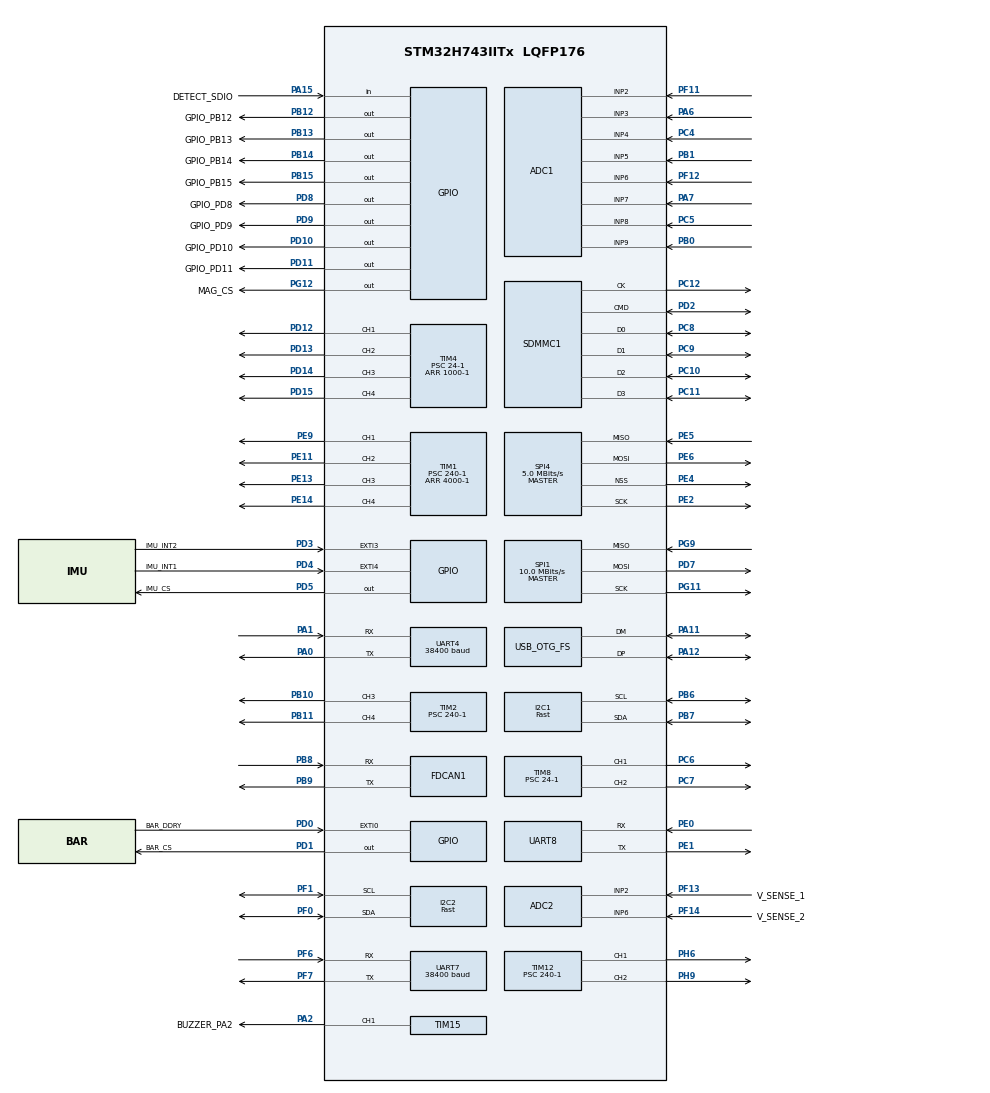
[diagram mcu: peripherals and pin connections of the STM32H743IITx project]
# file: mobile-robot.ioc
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ADC1.Channel-0\#ChannelRegularConversion=ADC_CHANNEL_2
ADC1.ClockPrescaler=ADC_CLOCK_ASYNC_DIV2
ADC1.NbrOfConversionFlag=1
ADC1.OffsetNumber-0\#ChannelRegularConversion=ADC_OFFSET_NONE
ADC1.OffsetSignedSaturation-0\#ChannelRegularConversion=DISABLE
ADC1.Rank-0\#ChannelRegularConversion=1
ADC1.SamplingTime-0\#ChannelRegularConversion=ADC_SAMPLETIME_1CYCLE_5
ADC1.master=1
ADC2.Channel-0\#ChannelRegularConversion=ADC_CHANNEL_2
ADC2.ClockPrescaler=ADC_CLOCK_ASYNC_DIV2
ADC2.NbrOfConversionFlag=1
ADC2.OffsetNumber-0\#ChannelRegularConversion=ADC_OFFSET_NONE
ADC2.OffsetSignedSaturation-0\#ChannelRegularConversion=DISABLE
ADC2.Rank-0\#ChannelRegularConversion=1
ADC2.SamplingTime-0\#ChannelRegularConversion=ADC_SAMPLETIME_1CYCLE_5
CORTEX_M7.default_mode_Activation=1
Dma.I2C1_RX.6.Direction=DMA_PERIPH_TO_MEMORY
Dma.I2C1_RX.6.EventEnable=DISABLE
Dma.I2C1_RX.6.FIFOMode=DMA_FIFOMODE_DISABLE
Dma.I2C1_RX.6.Instance=DMA1_Stream6
Dma.I2C1_RX.6.MemDataAlignment=DMA_MDATAALIGN_BYTE
Dma.I2C1_RX.6.MemInc=DMA_MINC_ENABLE
Dma.I2C1_RX.6.Mode=DMA_NORMAL
Dma.I2C1_RX.6.PeriphDataAlignment=DMA_PDATAALIGN_BYTE
Dma.I2C1_RX.6.PeriphInc=DMA_PINC_DISABLE
Dma.I2C1_RX.6.Polarity=HAL_DMAMUX_REQ_GEN_RISING
Dma.I2C1_RX.6.Priority=DMA_PRIORITY_LOW
Dma.I2C1_RX.6.RequestNumber=1
Dma.I2C1_RX.6.SignalID=NONE
Dma.I2C1_RX.6.SyncEnable=DISABLE
Dma.I2C1_RX.6.SyncPolarity=HAL_DMAMUX_SYNC_NO_EVENT
Dma.I2C1_RX.6.SyncRequestNumber=1
Dma.I2C1_RX.6.SyncSignalID=NONE
Dma.I2C1_TX.7.Direction=DMA_MEMORY_TO_PERIPH
Dma.I2C1_TX.7.EventEnable=DISABLE
Dma.I2C1_TX.7.FIFOMode=DMA_FIFOMODE_DISABLE
Dma.I2C1_TX.7.Instance=DMA1_Stream7
Dma.I2C1_TX.7.MemDataAlignment=DMA_MDATAALIGN_BYTE
Dma.I2C1_TX.7.MemInc=DMA_MINC_ENABLE
Dma.I2C1_TX.7.Mode=DMA_NORMAL
Dma.I2C1_TX.7.PeriphDataAlignment=DMA_PDATAALIGN_BYTE
Dma.I2C1_TX.7.PeriphInc=DMA_PINC_DISABLE
Dma.I2C1_TX.7.Polarity=HAL_DMAMUX_REQ_GEN_RISING
Dma.I2C1_TX.7.Priority=DMA_PRIORITY_LOW
Dma.I2C1_TX.7.RequestNumber=1
Dma.I2C1_TX.7.SignalID=NONE
Dma.I2C1_TX.7.SyncEnable=DISABLE
Dma.I2C1_TX.7.SyncPolarity=HAL_DMAMUX_SYNC_NO_EVENT
Dma.I2C1_TX.7.SyncRequestNumber=1
Dma.I2C1_TX.7.SyncSignalID=NONE
Dma.Request0=UART4_RX
Dma.Request1=UART4_TX
Dma.Request2=UART7_RX
Dma.Request3=UART7_TX
Dma.Request4=UART8_RX
Dma.Request5=UART8_TX
Dma.Request6=I2C1_RX
Dma.Request7=I2C1_TX
Dma.Request8=SPI1_RX
Dma.Request9=SPI1_TX
Dma.SPI1_RX.8.Direction=DMA_PERIPH_TO_MEMORY
Dma.SPI1_RX.8.EventEnable=DISABLE
Dma.SPI1_RX.8.FIFOMode=DMA_FIFOMODE_DISABLE
Dma.SPI1_RX.8.Instance=DMA2_Stream0
Dma.SPI1_RX.8.MemDataAlignment=DMA_MDATAALIGN_BYTE
Dma.SPI1_RX.8.MemInc=DMA_MINC_ENABLE
Dma.SPI1_RX.8.Mode=DMA_NORMAL
Dma.SPI1_RX.8.PeriphDataAlignment=DMA_PDATAALIGN_BYTE
Dma.SPI1_RX.8.PeriphInc=DMA_PINC_DISABLE
Dma.SPI1_RX.8.Polarity=HAL_DMAMUX_REQ_GEN_RISING
Dma.SPI1_RX.8.Priority=DMA_PRIORITY_LOW
Dma.SPI1_RX.8.RequestNumber=1
Dma.SPI1_RX.8.SignalID=NONE
Dma.SPI1_RX.8.SyncEnable=DISABLE
Dma.SPI1_RX.8.SyncPolarity=HAL_DMAMUX_SYNC_NO_EVENT
Dma.SPI1_RX.8.SyncRequestNumber=1
Dma.SPI1_RX.8.SyncSignalID=NONE
Dma.SPI1_TX.9.Direction=DMA_MEMORY_TO_PERIPH
Dma.SPI1_TX.9.EventEnable=DISABLE
Dma.SPI1_TX.9.FIFOMode=DMA_FIFOMODE_DISABLE
Dma.SPI1_TX.9.Instance=DMA2_Stream1
Dma.SPI1_TX.9.MemDataAlignment=DMA_MDATAALIGN_BYTE
Dma.SPI1_TX.9.MemInc=DMA_MINC_ENABLE
Dma.SPI1_TX.9.Mode=DMA_NORMAL
Dma.SPI1_TX.9.PeriphDataAlignment=DMA_PDATAALIGN_BYTE
Dma.SPI1_TX.9.PeriphInc=DMA_PINC_DISABLE
Dma.SPI1_TX.9.Polarity=HAL_DMAMUX_REQ_GEN_RISING
Dma.SPI1_TX.9.Priority=DMA_PRIORITY_LOW
Dma.SPI1_TX.9.RequestNumber=1
Dma.SPI1_TX.9.SignalID=NONE
Dma.SPI1_TX.9.SyncEnable=DISABLE
Dma.SPI1_TX.9.SyncPolarity=HAL_DMAMUX_SYNC_NO_EVENT
Dma.SPI1_TX.9.SyncRequestNumber=1
Dma.SPI1_TX.9.SyncSignalID=NONE
Dma.UART4_RX.0.Direction=DMA_PERIPH_TO_MEMORY
Dma.UART4_RX.0.EventEnable=DISABLE
Dma.UART4_RX.0.FIFOMode=DMA_FIFOMODE_DISABLE
Dma.UART4_RX.0.Instance=DMA1_Stream0
Dma.UART4_RX.0.MemDataAlignment=DMA_MDATAALIGN_BYTE
Dma.UART4_RX.0.MemInc=DMA_MINC_ENABLE
Dma.UART4_RX.0.Mode=DMA_NORMAL
Dma.UART4_RX.0.PeriphDataAlignment=DMA_PDATAALIGN_BYTE
Dma.UART4_RX.0.PeriphInc=DMA_PINC_DISABLE
Dma.UART4_RX.0.Polarity=HAL_DMAMUX_REQ_GEN_RISING
Dma.UART4_RX.0.Priority=DMA_PRIORITY_LOW
Dma.UART4_RX.0.RequestNumber=1
Dma.UART4_RX.0.SignalID=NONE
Dma.UART4_RX.0.SyncEnable=DISABLE
Dma.UART4_RX.0.SyncPolarity=HAL_DMAMUX_SYNC_NO_EVENT
Dma.UART4_RX.0.SyncRequestNumber=1
Dma.UART4_RX.0.SyncSignalID=NONE
Dma.UART4_TX.1.Direction=DMA_MEMORY_TO_PERIPH
Dma.UART4_TX.1.EventEnable=DISABLE
Dma.UART4_TX.1.FIFOMode=DMA_FIFOMODE_DISABLE
Dma.UART4_TX.1.Instance=DMA1_Stream1
Dma.UART4_TX.1.MemDataAlignment=DMA_MDATAALIGN_BYTE
Dma.UART4_TX.1.MemInc=DMA_MINC_ENABLE
Dma.UART4_TX.1.Mode=DMA_NORMAL
Dma.UART4_TX.1.PeriphDataAlignment=DMA_PDATAALIGN_BYTE
Dma.UART4_TX.1.PeriphInc=DMA_PINC_DISABLE
Dma.UART4_TX.1.Polarity=HAL_DMAMUX_REQ_GEN_RISING
Dma.UART4_TX.1.Priority=DMA_PRIORITY_LOW
Dma.UART4_TX.1.RequestNumber=1
Dma.UART4_TX.1.SignalID=NONE
Dma.UART4_TX.1.SyncEnable=DISABLE
Dma.UART4_TX.1.SyncPolarity=HAL_DMAMUX_SYNC_NO_EVENT
Dma.UART4_TX.1.SyncRequestNumber=1
Dma.UART4_TX.1.SyncSignalID=NONE
Dma.UART7_RX.2.Direction=DMA_PERIPH_TO_MEMORY
Dma.UART7_RX.2.EventEnable=DISABLE
Dma.UART7_RX.2.FIFOMode=DMA_FIFOMODE_DISABLE
Dma.UART7_RX.2.Instance=DMA1_Stream2
Dma.UART7_RX.2.MemDataAlignment=DMA_MDATAALIGN_BYTE
Dma.UART7_RX.2.MemInc=DMA_MINC_ENABLE
Dma.UART7_RX.2.Mode=DMA_NORMAL
Dma.UART7_RX.2.PeriphDataAlignment=DMA_PDATAALIGN_BYTE
Dma.UART7_RX.2.PeriphInc=DMA_PINC_DISABLE
Dma.UART7_RX.2.Polarity=HAL_DMAMUX_REQ_GEN_RISING
Dma.UART7_RX.2.Priority=DMA_PRIORITY_LOW
Dma.UART7_RX.2.RequestNumber=1
Dma.UART7_RX.2.SignalID=NONE
Dma.UART7_RX.2.SyncEnable=DISABLE
Dma.UART7_RX.2.SyncPolarity=HAL_DMAMUX_SYNC_NO_EVENT
Dma.UART7_RX.2.SyncRequestNumber=1
Dma.UART7_RX.2.SyncSignalID=NONE
Dma.UART7_TX.3.Direction=DMA_MEMORY_TO_PERIPH
Dma.UART7_TX.3.EventEnable=DISABLE
Dma.UART7_TX.3.FIFOMode=DMA_FIFOMODE_DISABLE
Dma.UART7_TX.3.Instance=DMA1_Stream3
Dma.UART7_TX.3.MemDataAlignment=DMA_MDATAALIGN_BYTE
Dma.UART7_TX.3.MemInc=DMA_MINC_ENABLE
Dma.UART7_TX.3.Mode=DMA_NORMAL
Dma.UART7_TX.3.PeriphDataAlignment=DMA_PDATAALIGN_BYTE
Dma.UART7_TX.3.PeriphInc=DMA_PINC_DISABLE
Dma.UART7_TX.3.Polarity=HAL_DMAMUX_REQ_GEN_RISING
Dma.UART7_TX.3.Priority=DMA_PRIORITY_LOW
Dma.UART7_TX.3.RequestNumber=1
Dma.UART7_TX.3.SignalID=NONE
Dma.UART7_TX.3.SyncEnable=DISABLE
Dma.UART7_TX.3.SyncPolarity=HAL_DMAMUX_SYNC_NO_EVENT
Dma.UART7_TX.3.SyncRequestNumber=1
Dma.UART7_TX.3.SyncSignalID=NONE
Dma.UART8_RX.4.Direction=DMA_PERIPH_TO_MEMORY
Dma.UART8_RX.4.EventEnable=DISABLE
Dma.UART8_RX.4.FIFOMode=DMA_FIFOMODE_DISABLE
Dma.UART8_RX.4.Instance=DMA1_Stream4
Dma.UART8_RX.4.MemDataAlignment=DMA_MDATAALIGN_BYTE
Dma.UART8_RX.4.MemInc=DMA_MINC_ENABLE
Dma.UART8_RX.4.Mode=DMA_NORMAL
Dma.UART8_RX.4.PeriphDataAlignment=DMA_PDATAALIGN_BYTE
Dma.UART8_RX.4.PeriphInc=DMA_PINC_DISABLE
Dma.UART8_RX.4.Polarity=HAL_DMAMUX_REQ_GEN_RISING
Dma.UART8_RX.4.Priority=DMA_PRIORITY_LOW
Dma.UART8_RX.4.RequestNumber=1
Dma.UART8_RX.4.SignalID=NONE
Dma.UART8_RX.4.SyncEnable=DISABLE
Dma.UART8_RX.4.SyncPolarity=HAL_DMAMUX_SYNC_NO_EVENT
Dma.UART8_RX.4.SyncRequestNumber=1
Dma.UART8_RX.4.SyncSignalID=NONE
Dma.UART8_TX.5.Direction=DMA_MEMORY_TO_PERIPH
Dma.UART8_TX.5.EventEnable=DISABLE
Dma.UART8_TX.5.FIFOMode=DMA_FIFOMODE_DISABLE
Dma.UART8_TX.5.Instance=DMA1_Stream5
Dma.UART8_TX.5.MemDataAlignment=DMA_MDATAALIGN_BYTE
Dma.UART8_TX.5.MemInc=DMA_MINC_ENABLE
Dma.UART8_TX.5.Mode=DMA_NORMAL
Dma.UART8_TX.5.PeriphDataAlignment=DMA_PDATAALIGN_BYTE
Dma.UART8_TX.5.PeriphInc=DMA_PINC_DISABLE
Dma.UART8_TX.5.Polarity=HAL_DMAMUX_REQ_GEN_RISING
Dma.UART8_TX.5.Priority=DMA_PRIORITY_LOW
Dma.UART8_TX.5.RequestNumber=1
Dma.UART8_TX.5.SignalID=NONE
Dma.UART8_TX.5.SyncEnable=DISABLE
Dma.UART8_TX.5.SyncPolarity=HAL_DMAMUX_SYNC_NO_EVENT
Dma.UART8_TX.5.SyncRequestNumber=1
Dma.UART8_TX.5.SyncSignalID=NONE
FATFS.BSP.number=1
FATFS._FS_EXFAT=1
FATFS._FS_TINY=1
FATFS._MAX_SS=4096
FATFS._USE_LFN=2
FATFS._USE_MUTEX=1
FATFS0.BSP.STBoard=false
FATFS0.BSP.api=Unknown
FATFS0.BSP.instance=PA15 (JTDI)
FATFS0.BSP.ip=GPIO
FATFS0.BSP.mode=Input
FATFS0.BSP.name=Detect_SDIO
FATFS0.BSP.solution=PA15 (JTDI)
FDCAN1.CalculateBaudRateNominal=1000000
FDCAN1.CalculateTimeBitNominal=1000
FDCAN1.CalculateTimeQuantumNominal=200.0
FREERTOS.HEAP_NUMBER=4
FREERTOS.Mutexes01=spi1Mutex,Dynamic,NULL,Depleted;spi4Mutex,Dynamic,NULL,Depleted;i2c1Mutex,Dynamic,NULL,Depleted;usbMutex,Dynamic,NULL,Depleted;fdcanMutex,Dynamic,NULL,Depleted;uart4Mutex,Dynamic,NULL,Available;uart7Mutex,Dynamic,NULL,Available
FREERTOS.Tasks01=defaultTask,8,128,StartDefaultTask,Default,NULL,Dynamic,NULL,NULL;encodersTask,24,512,StartEncodersTask,As external,NULL,Dynamic,NULL,NULL;fusionTask,24,8192,StartFusionTask,As external,NULL,Dynamic,NULL,NULL;debugTask,8,256,StartDebugTask,As external,NULL,Dynamic,NULL,NULL;controlTask,40,1024,StartControlTask,As external,NULL,Dynamic,NULL,NULL;barometerTask,24,512,StartBarometerTask,As external,NULL,Dynamic,NULL,NULL;imuTask,24,512,StartIMUTask,As external,NULL,Dynamic,NULL,NULL;magTask,24,2048,StartMagTask,As external,NULL,Dynamic,NULL,NULL;commTask,24,512,StartCommTask,As external,NULL,Dynamic,NULL,NULL;leftMotorTask,24,256,StartLeftMotorTask,As external,NULL,Dynamic,NULL,NULL;rightMotorTask,8,256,StartRightMotorTask,As external,NULL,Dynamic,NULL,NULL
FREERTOS.configCHECK_FOR_STACK_OVERFLOW=2
FREERTOS.configENABLE_FPU=0
FREERTOS.configMINIMAL_STACK_SIZE=128
FREERTOS.configRECORD_STACK_HIGH_ADDRESS=1
FREERTOS.configTOTAL_HEAP_SIZE=102400
I2C1.I2C_Speed_Mode=I2C_Fast
I2C1.OwnAddress=0x08
I2C1.Speed=400
I2C1.Timing=0x00B03FDB
I2C2.I2C_Speed_Mode=I2C_Fast
I2C2.Timing=0x00B03FDB
Mcu.Family=STM32H7
Mcu.Name=STM32H743IITx
Mcu.Package=LQFP176
NVIC.DMA1_Stream0_IRQn=true\:5\:0\:false\:false\:true\:true\:false\:true\:true
NVIC.DMA1_Stream1_IRQn=true\:5\:0\:false\:false\:true\:true\:false\:true\:true
NVIC.DMA1_Stream2_IRQn=true\:5\:0\:false\:false\:true\:true\:false\:true\:true
NVIC.DMA1_Stream3_IRQn=true\:5\:0\:false\:false\:true\:true\:false\:true\:true
NVIC.DMA1_Stream4_IRQn=true\:5\:0\:false\:false\:true\:true\:false\:true\:true
NVIC.DMA1_Stream5_IRQn=true\:5\:0\:false\:false\:true\:true\:false\:true\:true
NVIC.DMA1_Stream6_IRQn=true\:5\:0\:false\:false\:true\:true\:false\:true\:true
NVIC.DMA1_Stream7_IRQn=true\:5\:0\:false\:false\:true\:true\:false\:true\:true
NVIC.DMA2_Stream0_IRQn=true\:5\:0\:false\:false\:true\:true\:false\:true\:true
NVIC.DMA2_Stream1_IRQn=true\:5\:0\:false\:false\:true\:true\:false\:true\:true
NVIC.I2C1_ER_IRQn=true\:5\:0\:false\:false\:true\:true\:true\:true\:true
NVIC.I2C1_EV_IRQn=true\:5\:0\:false\:false\:true\:true\:true\:true\:true
NVIC.OTG_FS_EP1_IN_IRQn=true\:5\:0\:false\:false\:true\:true\:true\:true\:true
NVIC.OTG_FS_EP1_OUT_IRQn=true\:5\:0\:false\:false\:true\:true\:true\:true\:true
NVIC.OTG_FS_IRQn=true\:5\:0\:false\:false\:true\:true\:false\:true\:true
NVIC.PriorityGroup=NVIC_PRIORITYGROUP_4
NVIC.SDMMC1_IRQn=true\:5\:0\:false\:false\:true\:true\:true\:true\:true
NVIC.SPI1_IRQn=true\:5\:0\:false\:false\:true\:true\:false\:true\:true
NVIC.TIM6_DAC_IRQn=true\:15\:0\:false\:false\:true\:false\:false\:true\:true
NVIC.TimeBase=TIM6_DAC_IRQn
NVIC.TimeBaseIP=TIM6
NVIC.UART4_IRQn=true\:5\:0\:false\:false\:true\:true\:true\:true\:true
NVIC.UART7_IRQn=true\:5\:0\:false\:false\:true\:true\:true\:true\:true
NVIC.UART8_IRQn=true\:5\:0\:false\:false\:true\:true\:true\:true\:true
PA0.GPIO_ModeDefaultPP=GPIO_MODE_AF_PP
PA0.GPIO_PuPd=GPIO_PULLDOWN
PA0.GPIO_Speed=GPIO_SPEED_FREQ_LOW
PA0.Mode=Asynchronous
PA0.Signal=UART4_TX
PA1.GPIO_PuPd=GPIO_PULLDOWN
PA1.Mode=Asynchronous
PA1.Signal=UART4_RX
PA11.Mode=Device_Only
PA11.Signal=USB_OTG_FS_DM
PA12.Mode=Device_Only
PA12.Signal=USB_OTG_FS_DP
PA13\ (JTMS/SWDIO).Mode=Trace_Asynchronous_SW
PA13\ (JTMS/SWDIO).Signal=DEBUG_JTMS-SWDIO
PA14\ (JTCK/SWCLK).Mode=Trace_Asynchronous_SW
PA14\ (JTCK/SWCLK).Signal=DEBUG_JTCK-SWCLK
PA15\ (JTDI).GPIO_Label=DETECT_SDIO
PA15\ (JTDI).GPIO_PuPd=GPIO_PULLDOWN
PA15\ (JTDI).Signal=GPIO_Input
PA2.GPIO_Label=BUZZER_PA2
PA2.Signal=S_TIM15_CH1
PA6.Signal=ADCx_INP3
PA7.Signal=ADCx_INP7
PB0.Signal=ADCx_INP9
PB1.Signal=ADCx_INP5
PB10.Signal=S_TIM2_CH3
PB11.Signal=S_TIM2_CH4
PB12.GPIO_Label=GPIO_PB12
PB12.Signal=GPIO_Output
PB13.GPIO_Label=GPIO_PB13
PB13.Signal=GPIO_Output
PB14.GPIO_Label=GPIO_PB14
PB14.Signal=GPIO_Output
PB15.GPIO_Label=GPIO_PB15
PB15.Signal=GPIO_Output
PB3\ (JTDO/TRACESWO).Mode=Trace_Asynchronous_SW
PB3\ (JTDO/TRACESWO).Signal=DEBUG_JTDO-SWO
PB6.GPIO_Speed=GPIO_SPEED_FREQ_VERY_HIGH
PB6.Mode=I2C
PB6.Signal=I2C1_SCL
PB7.GPIO_Speed=GPIO_SPEED_FREQ_VERY_HIGH
PB7.Mode=I2C
PB7.Signal=I2C1_SDA
PB8.Mode=FDCAN_Activate
PB8.Signal=FDCAN1_RX
PB9.Mode=FDCAN_Activate
PB9.Signal=FDCAN1_TX
PC10.GPIO_PuPd=GPIO_PULLUP
PC10.GPIO_Speed_High_Default=GPIO_SPEED_FREQ_VERY_HIGH
PC10.Mode=SD_4_bits_Wide_bus
PC10.Signal=SDMMC1_D2
PC11.GPIO_PuPd=GPIO_PULLUP
PC11.GPIO_Speed_High_Default=GPIO_SPEED_FREQ_VERY_HIGH
PC11.Mode=SD_4_bits_Wide_bus
PC11.Signal=SDMMC1_D3
PC12.GPIO_PuPd=GPIO_NOPULL
PC12.GPIO_Speed_High_Default=GPIO_SPEED_FREQ_VERY_HIGH
PC12.Mode=SD_4_bits_Wide_bus
PC12.Signal=SDMMC1_CK
PC4.Signal=ADCx_INP4
PC5.Signal=ADCx_INP8
PC6.Signal=S_TIM8_CH1
PC7.Signal=S_TIM8_CH2
PC8.GPIO_PuPd=GPIO_PULLUP
PC8.GPIO_Speed_High_Default=GPIO_SPEED_FREQ_VERY_HIGH
PC8.Mode=SD_4_bits_Wide_bus
PC8.Signal=SDMMC1_D0
PC9.GPIO_PuPd=GPIO_PULLUP
PC9.GPIO_Speed_High_Default=GPIO_SPEED_FREQ_VERY_HIGH
PC9.Mode=SD_4_bits_Wide_bus
PC9.Signal=SDMMC1_D1
PD0.GPIO_Label=BAR_DDRY
PD0.Signal=GPXTI0
PD1.GPIO_Label=BAR_CS
PD1.GPIO_ModeDefaultOutputPP=GPIO_MODE_OUTPUT_PP
PD1.GPIO_PuPd=GPIO_NOPULL
PD1.PinState=GPIO_PIN_SET
PD1.Signal=GPIO_Output
PD10.GPIO_Label=GPIO_PD10
PD10.Signal=GPIO_Output
PD11.GPIO_Label=GPIO_PD11
PD11.Signal=GPIO_Output
PD12.Signal=S_TIM4_CH1
PD13.Signal=S_TIM4_CH2
PD14.Signal=S_TIM4_CH3
PD15.Signal=S_TIM4_CH4
PD2.GPIO_PuPd=GPIO_PULLUP
PD2.GPIO_Speed_High_Default=GPIO_SPEED_FREQ_VERY_HIGH
PD2.Mode=SD_4_bits_Wide_bus
PD2.Signal=SDMMC1_CMD
PD3.GPIO_Label=IMU_INT2
PD3.Signal=GPXTI3
PD4.GPIO_Label=IMU_INT1
PD4.Signal=GPXTI4
PD5.GPIO_Label=IMU_CS
PD5.GPIO_ModeDefaultOutputPP=GPIO_MODE_OUTPUT_PP
PD5.GPIO_PuPd=GPIO_NOPULL
PD5.PinState=GPIO_PIN_SET
PD5.Signal=GPIO_Output
PD7.GPIO_Speed=GPIO_SPEED_FREQ_LOW
PD7.Mode=Full_Duplex_Master
PD7.Signal=SPI1_MOSI
PD8.GPIO_Label=GPIO_PD8
PD8.Signal=GPIO_Output
PD9.GPIO_Label=GPIO_PD9
PD9.Signal=GPIO_Output
PE0.Mode=Asynchronous
PE0.Signal=UART8_RX
PE1.Mode=Asynchronous
PE1.Signal=UART8_TX
PE11.Signal=S_TIM1_CH2
PE13.Signal=S_TIM1_CH3
PE14.Signal=S_TIM1_CH4
PE2.GPIO_Speed=GPIO_SPEED_FREQ_LOW
PE2.Mode=Full_Duplex_Master
PE2.Signal=SPI4_SCK
PE4.GPIO_Speed=GPIO_SPEED_FREQ_LOW
PE4.Mode=NSS_Signal_Hard_Output
PE4.Signal=SPI4_NSS
PE5.GPIO_Speed=GPIO_SPEED_FREQ_LOW
PE5.Mode=Full_Duplex_Master
PE5.Signal=SPI4_MISO
PE6.GPIO_Speed=GPIO_SPEED_FREQ_LOW
PE6.Mode=Full_Duplex_Master
PE6.Signal=SPI4_MOSI
PE9.Signal=S_TIM1_CH1
PF0.GPIO_Speed=GPIO_SPEED_FREQ_VERY_HIGH
PF0.Mode=I2C
PF0.Signal=I2C2_SDA
PF1.GPIO_Speed=GPIO_SPEED_FREQ_VERY_HIGH
PF1.Mode=I2C
PF1.Signal=I2C2_SCL
PF11.Mode=IN2-Single-Ended
PF11.Signal=ADC1_INP2
PF12.Mode=IN6-Single-Ended
PF12.Signal=ADC1_INP6
PF13.GPIO_Label=V_SENSE_1
PF13.Mode=IN2-Single-Ended
PF13.Signal=ADC2_INP2
PF14.GPIO_Label=V_SENSE_2
PF14.Mode=IN6-Single-Ended
PF14.Signal=ADC2_INP6
PF6.GPIO_PuPd=GPIO_PULLDOWN
PF6.Mode=Asynchronous
PF6.Signal=UART7_RX
PF7.GPIO_PuPd=GPIO_PULLDOWN
PF7.Mode=Asynchronous
PF7.Signal=UART7_TX
PG11.GPIO_Speed=GPIO_SPEED_FREQ_LOW
PG11.Mode=Full_Duplex_Master
PG11.Signal=SPI1_SCK
PG12.GPIO_Label=MAG_CS
PG12.GPIO_ModeDefaultOutputPP=GPIO_MODE_OUTPUT_PP
PG12.PinState=GPIO_PIN_SET
PG12.Signal=GPIO_Output
PG9.GPIO_Speed=GPIO_SPEED_FREQ_LOW
PG9.Mode=Full_Duplex_Master
PG9.Signal=SPI1_MISO
PH0-OSC_IN\ (PH0).Mode=HSE-External-Oscillator
PH0-OSC_IN\ (PH0).Signal=RCC_OSC_IN
PH1-OSC_OUT\ (PH1).Mode=HSE-External-Oscillator
PH1-OSC_OUT\ (PH1).Signal=RCC_OSC_OUT
PH6.Signal=S_TIM12_CH1
PH9.Signal=S_TIM12_CH2
ProjectManager.HeapSize=0x1200
ProjectManager.StackSize=0x1200
ProjectManager.TargetToolchain=Makefile
RCC.ADCFreq_Value=80000000
RCC.APB1Freq_Value=120000000
RCC.APB2Freq_Value=120000000
RCC.APB3Freq_Value=120000000
RCC.APB4Freq_Value=120000000
RCC.CKPERSourceSelection=RCC_CLKPSOURCE_HSE
RCC.CortexFreq_Value=480000000
RCC.D1PPRE=RCC_APB3_DIV2
RCC.D2PPRE1=RCC_APB1_DIV2
RCC.D2PPRE2=RCC_APB2_DIV2
RCC.D3PPRE=RCC_APB4_DIV2
RCC.DIVM1=1
RCC.DIVM2=1
RCC.DIVM3=8
RCC.DIVN1=60
RCC.DIVN2=30
RCC.DIVN3=96
RCC.DIVP2=6
RCC.DIVQ1=4
RCC.DIVQ2=6
RCC.DIVQ3=4
RCC.DIVR2=10
RCC.EnbaleCSS=false
RCC.FDCANCLockSelection=RCC_FDCANCLKSOURCE_PLL2
RCC.FLatency-AdvancedSettings=FLASH_LATENCY_4
RCC.HCLKFreq_Value=240000000
RCC.HPRE=RCC_HCLK_DIV2
RCC.HSE_VALUE=16000000
RCC.LockedElements=USBoutput,SPI123output,SPI45output
RCC.PLL1_VCI_Range-AdvancedSettings=RCC_PLL1VCIRANGE_0
RCC.PLL1_VCO_SEL-AdvancedSettings=RCC_PLL1VCOMEDIUM
RCC.PLL2FRACN=0
RCC.PLL2_VCI_Range-AdvancedSettings=RCC_PLL2VCIRANGE_0
RCC.PLL3FRACN=0
RCC.PLL3_VCI_Range-AdvancedSettings=RCC_PLL3VCIRANGE_0
RCC.PLL3_VCO_SEL-AdvancedSettings=RCC_PLL3VCOMEDIUM
RCC.PLLFRACN=0
RCC.PLLSourceVirtual=RCC_PLLSOURCE_HSE
RCC.SAI4BCLockSelection=RCC_SAI4BCLKSOURCE_PLL2
RCC.SDMMC1CLockSelection=RCC_SDMMCCLKSOURCE_PLL2
RCC.SPI123CLockSelection=RCC_SPI123CLKSOURCE_PLL2
RCC.SYSCLKFreq_VALUE=480000000
RCC.SYSCLKSource=RCC_SYSCLKSOURCE_PLLCLK
RCC.Spi45ClockSelection=RCC_SPI45CLKSOURCE_PLL2
RCC.Tim2Mul=1
RCC.USBCLockSelection=RCC_USBCLKSOURCE_PLL3
RCC.USBFreq_Value=48000000
SDMMC1.ClockDiv=8
SH.ADCx_INP3.0=ADC1_INP3,IN3-Single-Ended
SH.ADCx_INP4.0=ADC1_INP4,IN4-Single-Ended
SH.ADCx_INP5.0=ADC1_INP5,IN5-Single-Ended
SH.ADCx_INP7.0=ADC1_INP7,IN7-Single-Ended
SH.ADCx_INP8.0=ADC1_INP8,IN8-Single-Ended
SH.ADCx_INP9.0=ADC1_INP9,IN9-Single-Ended
SH.S_TIM12_CH1.0=TIM12_CH1,PWM Generation1 CH1
SH.S_TIM12_CH2.0=TIM12_CH2,PWM Generation2 CH2
SH.S_TIM15_CH1.0=TIM15_CH1,PWM Generation1 CH1
SH.S_TIM1_CH1.0=TIM1_CH1,PWM Generation1 CH1
SH.S_TIM1_CH2.0=TIM1_CH2,PWM Generation2 CH2
SH.S_TIM1_CH3.0=TIM1_CH3,PWM Generation3 CH3
SH.S_TIM1_CH4.0=TIM1_CH4,PWM Generation4 CH4
SH.S_TIM2_CH3.0=TIM2_CH3,PWM Generation3 CH3
SH.S_TIM2_CH4.0=TIM2_CH4,PWM Generation4 CH4
SH.S_TIM4_CH1.0=TIM4_CH1,PWM Generation1 CH1
SH.S_TIM4_CH2.0=TIM4_CH2,PWM Generation2 CH2
SH.S_TIM4_CH3.0=TIM4_CH3,PWM Generation3 CH3
SH.S_TIM4_CH4.0=TIM4_CH4,PWM Generation4 CH4
SH.S_TIM8_CH1.0=TIM8_CH1,PWM Generation1 CH1
SH.S_TIM8_CH2.0=TIM8_CH2,PWM Generation2 CH2
SPI1.BaudRatePrescaler=SPI_BAUDRATEPRESCALER_8
SPI1.CalculateBaudRate=10.0 MBits/s
SPI1.DataSize=SPI_DATASIZE_8BIT
SPI1.Direction=SPI_DIRECTION_2LINES
SPI1.Mode=SPI_MODE_MASTER
SPI1.VirtualType=VM_MASTER
SPI4.BaudRatePrescaler=SPI_BAUDRATEPRESCALER_16
SPI4.CalculateBaudRate=5.0 MBits/s
SPI4.DataSize=SPI_DATASIZE_8BIT
SPI4.Direction=SPI_DIRECTION_2LINES
SPI4.Mode=SPI_MODE_MASTER
SPI4.VirtualNSS=VM_NSSHARD
SPI4.VirtualType=VM_MASTER
STMicroelectronics.X-CUBE-MEMS1.10.0.0.BoardOoPartJjAccGyrJjLSM6DSO=SPI
STMicroelectronics.X-CUBE-MEMS1.10.0.0.BoardOoPartJjMagJjLIS2MDL=SPI
STMicroelectronics.X-CUBE-MEMS1.10.0.0.BoardOoPartJjPressTempJjLPS22HH=SPI
TIM1.Channel-PWM\ Generation1\ CH1=TIM_CHANNEL_1
TIM1.Channel-PWM\ Generation2\ CH2=TIM_CHANNEL_2
TIM1.Channel-PWM\ Generation3\ CH3=TIM_CHANNEL_3
TIM1.Channel-PWM\ Generation4\ CH4=TIM_CHANNEL_4
TIM1.Period=4000-1
TIM1.Prescaler=240-1
TIM12.Channel-PWM\ Generation1\ CH1=TIM_CHANNEL_1
TIM12.Channel-PWM\ Generation2\ CH2=TIM_CHANNEL_2
TIM12.Period=4000-1
TIM12.Prescaler=240-1
TIM15.Channel-PWM\ Generation1\ CH1=TIM_CHANNEL_1
TIM15.Period=1000-1
TIM15.Prescaler=120-1
TIM2.Channel-PWM\ Generation3\ CH3=TIM_CHANNEL_3
TIM2.Channel-PWM\ Generation4\ CH4=TIM_CHANNEL_4
TIM2.Period=4000-1
TIM2.Prescaler=240-1
TIM4.Channel-PWM\ Generation1\ CH1=TIM_CHANNEL_1
TIM4.Channel-PWM\ Generation2\ CH2=TIM_CHANNEL_2
TIM4.Channel-PWM\ Generation3\ CH3=TIM_CHANNEL_3
TIM4.Channel-PWM\ Generation4\ CH4=TIM_CHANNEL_4
TIM4.Period=1000-1
TIM4.Prescaler=24-1
TIM8.Channel-PWM\ Generation1\ CH1=TIM_CHANNEL_1
TIM8.Channel-PWM\ Generation2\ CH2=TIM_CHANNEL_2
TIM8.Period=1000-1
TIM8.Prescaler=24-1
UART4.BaudRate=38400
UART4.DataInvertParam=UART_ADVFEATURE_DATAINV_DISABLE
UART4.RxPinLevelInvertParam=UART_ADVFEATURE_RXINV_ENABLE
UART4.SwapParam=UART_ADVFEATURE_SWAP_DISABLE
UART4.TxPinLevelInvertParam=UART_ADVFEATURE_TXINV_ENABLE
UART7.BaudRate=38400
UART7.RxPinLevelInvertParam=UART_ADVFEATURE_RXINV_ENABLE
UART7.SwapParam=UART_ADVFEATURE_SWAP_DISABLE
UART7.TxPinLevelInvertParam=UART_ADVFEATURE_TXINV_ENABLE
USB_DEVICE.CLASS_NAME_FS=CDC
USB_DEVICE.VirtualMode-CDC_FS=Cdc
USB_DEVICE.VirtualModeFS=Cdc_FS
USB_OTG_FS.VirtualMode=Device_Only
VP_FATFS_VS_SDIO.Mode=SDIO
VP_FREERTOS_VS_CMSIS_V2.Mode=CMSIS_V2
VP_MEMORYMAP_VS_MEMORYMAP.Mode=CurAppReg
VP_STMicroelectronics.X-CUBE-MEMS1_VS_BoardOoPartJjAccGyr_5.5.0_10.0.0.Mode=BoardOoPartJjAccGyr
VP_STMicroelectronics.X-CUBE-MEMS1_VS_BoardOoPartJjMag_5.4.0_10.0.0.Mode=BoardOoPartJjMag
VP_STMicroelectronics.X-CUBE-MEMS1_VS_BoardOoPartJjPressTemp_5.6.0_10.0.0.Mode=BoardOoPartJjPressTemp
VP_SYS_VS_tim6.Mode=TIM6
VP_USB_DEVICE_VS_USB_DEVICE_CDC_FS.Mode=CDC_FS
board=custom

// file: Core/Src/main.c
/* USER CODE BEGIN Header */
/**
 ******************************************************************************
 * @file           : main.c
 * @brief          : Main program body
 ******************************************************************************
 * @attention
 *
 * Copyright (c) 2025 STMicroelectronics.
 * All rights reserved.
 *
 * This software is licensed under terms that can be found in the LICENSE file
 * in the root directory of this software component.
 * If no LICENSE file comes with this software, it is provided AS-IS.
 *
 ******************************************************************************
 */
/* USER CODE END Header */
#include "main.h"
#include "cmsis_os.h"
#include "adc.h"
#include "fatfs.h"
#include "fdcan.h"
#include "i2c.h"
#include "memorymap.h"
#include "sdmmc.h"
#include "spi.h"
#include "tim.h"
#include "usart.h"
#include "usb_device.h"
#include "gpio.h"

/* USER CODE BEGIN Includes */

#include <stdio.h>
#include "usbd_cdc_if.h"

/* USER CODE END Includes */

void SystemClock_Config(void);
void PeriphCommonClock_Config(void);
static void MPU_Config(void);
void MX_FREERTOS_Init(void);

/* USER CODE BEGIN 0 */

extern osMutexId_t usbMutexHandle;

int _write(int file, char *ptr, int length)
{
  (void)file;

  // Wait for the USB mutex
  osMutexAcquire(usbMutexHandle, osWaitForever);

  // Transmit the data
  CDC_Transmit_FS((uint8_t *)ptr, length);

  // Release the USB mutex
  osMutexRelease(usbMutexHandle);

  return length;
}

/* USER CODE END 0 */

int main(void)
{

  /* MPU Configuration--------------------------------------------------------*/
  MPU_Config();

  /* MCU Configuration--------------------------------------------------------*/

  /* Reset of all peripherals, Initializes the Flash interface and the Systick. */
  HAL_Init();

  /* Configure the system clock */
  SystemClock_Config();

  /* Configure the peripherals common clocks */
  PeriphCommonClock_Config();

  /* Initialize all configured peripherals */
  MX_GPIO_Init();
  MX_ADC1_Init();
  MX_FDCAN1_Init();
  MX_I2C1_Init();
  MX_I2C2_Init();
  MX_SDMMC1_SD_Init();
  MX_SPI1_Init();
  MX_SPI4_Init();
  MX_TIM1_Init();
  MX_TIM2_Init();
  MX_TIM12_Init();
  MX_TIM15_Init();
  MX_UART8_Init();
  MX_FATFS_Init();
  MX_ADC2_Init();
  MX_TIM4_Init();
  MX_TIM8_Init();
  MX_UART4_Init();
  MX_UART7_Init();
  /* USER CODE BEGIN 2 */

  MX_USB_DEVICE_Init();

  /* USER CODE END 2 */

  /* Init scheduler */
  osKernelInitialize();

  /* Call init function for freertos objects (in cmsis_os2.c) */
  MX_FREERTOS_Init();

  /* Start scheduler */
  osKernelStart();

  /* We should never get here as control is now taken by the scheduler */

  /* Infinite loop */
  while (1)
  {

  }
}

void SystemClock_Config(void)
{
  RCC_OscInitTypeDef RCC_OscInitStruct = {0};
  RCC_ClkInitTypeDef RCC_ClkInitStruct = {0};

  /** Supply configuration update enable
  */
  HAL_PWREx_ConfigSupply(PWR_LDO_SUPPLY);

  /** Configure the main internal regulator output voltage
  */
  __HAL_PWR_VOLTAGESCALING_CONFIG(PWR_REGULATOR_VOLTAGE_SCALE1);

  while(!__HAL_PWR_GET_FLAG(PWR_FLAG_VOSRDY)) {}

  __HAL_RCC_SYSCFG_CLK_ENABLE();
  __HAL_PWR_VOLTAGESCALING_CONFIG(PWR_REGULATOR_VOLTAGE_SCALE0);

  while(!__HAL_PWR_GET_FLAG(PWR_FLAG_VOSRDY)) {}

  /** Initializes the RCC Oscillators according to the specified parameters
  * in the RCC_OscInitTypeDef structure.
  */
  RCC_OscInitStruct.OscillatorType = RCC_OSCILLATORTYPE_HSI48|RCC_OSCILLATORTYPE_HSE;
  RCC_OscInitStruct.HSEState = RCC_HSE_ON;
  RCC_OscInitStruct.HSI48State = RCC_HSI48_ON;
  RCC_OscInitStruct.PLL.PLLState = RCC_PLL_ON;
  RCC_OscInitStruct.PLL.PLLSource = RCC_PLLSOURCE_HSE;
  RCC_OscInitStruct.PLL.PLLM = 1;
  RCC_OscInitStruct.PLL.PLLN = 60;
  RCC_OscInitStruct.PLL.PLLP = 2;
  RCC_OscInitStruct.PLL.PLLQ = 8;
  RCC_OscInitStruct.PLL.PLLR = 2;
  RCC_OscInitStruct.PLL.PLLRGE = RCC_PLL1VCIRANGE_3;
  RCC_OscInitStruct.PLL.PLLVCOSEL = RCC_PLL1VCOWIDE;
  RCC_OscInitStruct.PLL.PLLFRACN = 0;
  if (HAL_RCC_OscConfig(&RCC_OscInitStruct) != HAL_OK)
  {
    Error_Handler();
  }

  /** Initializes the CPU, AHB and APB buses clocks
  */
  RCC_ClkInitStruct.ClockType = RCC_CLOCKTYPE_HCLK|RCC_CLOCKTYPE_SYSCLK
                              |RCC_CLOCKTYPE_PCLK1|RCC_CLOCKTYPE_PCLK2
                              |RCC_CLOCKTYPE_D3PCLK1|RCC_CLOCKTYPE_D1PCLK1;
  RCC_ClkInitStruct.SYSCLKSource = RCC_SYSCLKSOURCE_PLLCLK;
  RCC_ClkInitStruct.SYSCLKDivider = RCC_SYSCLK_DIV1;
  RCC_ClkInitStruct.AHBCLKDivider = RCC_HCLK_DIV2;
  RCC_ClkInitStruct.APB3CLKDivider = RCC_APB3_DIV2;
  RCC_ClkInitStruct.APB1CLKDivider = RCC_APB1_DIV2;
  RCC_ClkInitStruct.APB2CLKDivider = RCC_APB2_DIV2;
  RCC_ClkInitStruct.APB4CLKDivider = RCC_APB4_DIV2;

  if (HAL_RCC_ClockConfig(&RCC_ClkInitStruct, FLASH_LATENCY_4) != HAL_OK)
  {
    Error_Handler();
  }
}

void PeriphCommonClock_Config(void)
{
  RCC_PeriphCLKInitTypeDef PeriphClkInitStruct = {0};

  /** Initializes the peripherals clock
  */
  PeriphClkInitStruct.PeriphClockSelection = RCC_PERIPHCLK_ADC|RCC_PERIPHCLK_SDMMC
                              |RCC_PERIPHCLK_SPI1|RCC_PERIPHCLK_SPI4
                              |RCC_PERIPHCLK_UART8|RCC_PERIPHCLK_UART7
                              |RCC_PERIPHCLK_UART4;
  PeriphClkInitStruct.PLL2.PLL2M = 1;
  PeriphClkInitStruct.PLL2.PLL2N = 10;
  PeriphClkInitStruct.PLL2.PLL2P = 2;
  PeriphClkInitStruct.PLL2.PLL2Q = 2;
  PeriphClkInitStruct.PLL2.PLL2R = 2;
  PeriphClkInitStruct.PLL2.PLL2RGE = RCC_PLL2VCIRANGE_3;
  PeriphClkInitStruct.PLL2.PLL2VCOSEL = RCC_PLL2VCOMEDIUM;
  PeriphClkInitStruct.PLL2.PLL2FRACN = 0;
  PeriphClkInitStruct.SdmmcClockSelection = RCC_SDMMCCLKSOURCE_PLL2;
  PeriphClkInitStruct.Spi123ClockSelection = RCC_SPI123CLKSOURCE_PLL2;
  PeriphClkInitStruct.Spi45ClockSelection = RCC_SPI45CLKSOURCE_PLL2;
  PeriphClkInitStruct.Usart234578ClockSelection = RCC_USART234578CLKSOURCE_PLL2;
  PeriphClkInitStruct.AdcClockSelection = RCC_ADCCLKSOURCE_PLL2;
  if (HAL_RCCEx_PeriphCLKConfig(&PeriphClkInitStruct) != HAL_OK)
  {
    Error_Handler();
  }
}

 /* MPU Configuration */

void MPU_Config(void)
{
  MPU_Region_InitTypeDef MPU_InitStruct = {0};

  /* Disables the MPU */
  HAL_MPU_Disable();

  /** Initializes and configures the Region and the memory to be protected
  */
  MPU_InitStruct.Enable = MPU_REGION_ENABLE;
  MPU_InitStruct.Number = MPU_REGION_NUMBER0;
  MPU_InitStruct.BaseAddress = 0x0;
  MPU_InitStruct.Size = MPU_REGION_SIZE_4GB;
  MPU_InitStruct.SubRegionDisable = 0x87;
  MPU_InitStruct.TypeExtField = MPU_TEX_LEVEL0;
  MPU_InitStruct.AccessPermission = MPU_REGION_NO_ACCESS;
  MPU_InitStruct.DisableExec = MPU_INSTRUCTION_ACCESS_DISABLE;
  MPU_InitStruct.IsShareable = MPU_ACCESS_SHAREABLE;
  MPU_InitStruct.IsCacheable = MPU_ACCESS_NOT_CACHEABLE;
  MPU_InitStruct.IsBufferable = MPU_ACCESS_NOT_BUFFERABLE;

  HAL_MPU_ConfigRegion(&MPU_InitStruct);
  /* Enables the MPU */
  HAL_MPU_Enable(MPU_PRIVILEGED_DEFAULT);

}

void HAL_TIM_PeriodElapsedCallback(TIM_HandleTypeDef *htim)
{
  if (htim->Instance == TIM6) {
    HAL_IncTick();
  }
}

void Error_Handler(void)
{
  __disable_irq();
  while (1)
  {
  }
}

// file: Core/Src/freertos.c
/* USER CODE BEGIN Header */
/**
 ******************************************************************************
 * File Name          : freertos.c
 * Description        : Code for freertos applications
 ******************************************************************************
 * @attention
 *
 * Copyright (c) 2025 STMicroelectronics.
 * All rights reserved.
 *
 * This software is licensed under terms that can be found in the LICENSE file
 * in the root directory of this software component.
 * If no LICENSE file comes with this software, it is provided AS-IS.
 *
 ******************************************************************************
 */
/* USER CODE END Header */

#include "FreeRTOS.h"
#include "task.h"
#include "main.h"
#include "cmsis_os.h"

/* USER CODE BEGIN Includes */

#include "tim.h"
#include "spi.h"
#include "i2c.h"
#include <stdio.h>
#include <lis2mdl.h>
#include <lsm6dso.h>

/* USER CODE END Includes */

/* Definitions for defaultTask */
osThreadId_t defaultTaskHandle;
const osThreadAttr_t defaultTask_attributes = {
    .name = "defaultTask",
    .stack_size = 512 * 4,
    .priority = (osPriority_t)osPriorityNormal,
};
/* Definitions for imuTask */
osThreadId_t imuTaskHandle;
const osThreadAttr_t imuTask_attributes = {
    .name = "imuTask",
    .stack_size = 512 * 4,
    .priority = (osPriority_t)osPriorityNormal,
};
/* Definitions for magTask */
osThreadId_t magTaskHandle;
const osThreadAttr_t magTask_attributes = {
    .name = "magTask",
    .stack_size = 512 * 4,
    .priority = (osPriority_t)osPriorityNormal,
};
/* Definitions for encodersTask */
osThreadId_t encodersTaskHandle;
const osThreadAttr_t encodersTask_attributes = {
    .name = "encodersTask",
    .stack_size = 512 * 4,
    .priority = (osPriority_t)osPriorityNormal,
};
/* Definitions for spi1Mutex */
osMutexId_t spi1MutexHandle;
const osMutexAttr_t spi1Mutex_attributes = {
    .name = "spi1Mutex"};
/* Definitions for spi4Mutex */
osMutexId_t spi4MutexHandle;
const osMutexAttr_t spi4Mutex_attributes = {
    .name = "spi4Mutex"};
/* Definitions for i2c1Mutex */
osMutexId_t i2c1MutexHandle;
const osMutexAttr_t i2c1Mutex_attributes = {
    .name = "i2c1Mutex"};
/* Definitions for usbMutex */
osMutexId_t usbMutexHandle;
const osMutexAttr_t usbMutex_attributes = {
    .name = "usbMutex"};
/* Definitions for fdcanMutex */
osMutexId_t fdcanMutexHandle;
const osMutexAttr_t fdcanMutex_attributes = {
    .name = "fdcanMutex"};

void StartDefaultTask(void *argument);
extern void StartImuTask(void *argument);
extern void StartMagTask(void *argument);
extern void StartEncodersTask(void *argument);

extern void MX_USB_DEVICE_Init(void);
void MX_FREERTOS_Init(void); /* (MISRA C 2004 rule 8.1) */

void MX_FREERTOS_Init(void)
{
  /* Create the mutex(es) */
  /* creation of spi1Mutex */
  spi1MutexHandle = osMutexNew(&spi1Mutex_attributes);

  /* creation of spi4Mutex */
  spi4MutexHandle = osMutexNew(&spi4Mutex_attributes);

  /* creation of i2c1Mutex */
  i2c1MutexHandle = osMutexNew(&i2c1Mutex_attributes);

  /* creation of usbMutex */
  usbMutexHandle = osMutexNew(&usbMutex_attributes);

  /* creation of fdcanMutex */
  fdcanMutexHandle = osMutexNew(&fdcanMutex_attributes);

  /* Create the thread(s) */
  /* creation of defaultTask */
  defaultTaskHandle = osThreadNew(StartDefaultTask, NULL, &defaultTask_attributes);

  /* creation of imuTask */
  imuTaskHandle = osThreadNew(StartImuTask, NULL, &imuTask_attributes);

  /* creation of magTask */
  magTaskHandle = osThreadNew(StartMagTask, NULL, &magTask_attributes);

  /* creation of encodersTask */
  encodersTaskHandle = osThreadNew(StartEncodersTask, NULL, &encodersTask_attributes);

}

void StartDefaultTask(void *argument)
{
  /* init code for USB_DEVICE */
  // MX_USB_DEVICE_Init();
  /* USER CODE BEGIN StartDefaultTask */

  // // GREEN LEDs
  // htim4.Instance->CCR1 = 100;
  // htim4.Instance->CCR2 = 100;
  // htim4.Instance->CCR3 = 100;

  // // RED LEDs
  // htim4.Instance->CCR4 = 100;
  // htim8.Instance->CCR1 = 100;
  // htim8.Instance->CCR2 = 100;

  // GREEN LEDs
  HAL_TIM_PWM_Start(&htim4, TIM_CHANNEL_1);
  HAL_TIM_PWM_Start(&htim4, TIM_CHANNEL_2);
  HAL_TIM_PWM_Start(&htim4, TIM_CHANNEL_3);

  // RED LEDs
  HAL_TIM_PWM_Start(&htim4, TIM_CHANNEL_4);
  HAL_TIM_PWM_Start(&htim8, TIM_CHANNEL_1);
  HAL_TIM_PWM_Start(&htim8, TIM_CHANNEL_2);

  // BUZZER
  HAL_TIM_PWM_Start(&htim15, TIM_CHANNEL_1);

  // htim15.Instance->CCR1 = 500;

  uint16_t pwm = 0;

  /* Infinite loop */
  for (;;)
  {
    // printf("Hello World!\n");

    // GREEN LEDs
    htim4.Instance->CCR4 = pwm % 300;
    htim8.Instance->CCR1 = (pwm + 100) % 300;
    htim8.Instance->CCR2 = (pwm + 200) % 300;

    pwm += 2;
    pwm %= 300;

    osDelay(10);
  }
  /* USER CODE END StartDefaultTask */
}

/* USER CODE BEGIN Application */

// LSM6DSO

LSM6DSO_Object_t lsm6dso;

int32_t Write_LSM6DSO(void *handle, uint8_t reg, uint8_t *data, uint16_t len)
{
  return SPI_Write_Register(&hspi1, &spi1MutexHandle, IMU_CS_GPIO_Port, IMU_CS_Pin, reg, data, len);
}

int32_t Read_LSM6DSO(void *handle, uint8_t reg, uint8_t *data, uint16_t len)
{
  return SPI_Read_Register(&hspi1, &spi1MutexHandle, IMU_CS_GPIO_Port, IMU_CS_Pin, reg, data, len);
}

void StartImuTask(void *argument)
{
  lsm6dso.Ctx.handle = &hspi1;
  lsm6dso.Ctx.write_reg = Write_LSM6DSO;
  lsm6dso.Ctx.read_reg = Read_LSM6DSO;
  lsm6dso.Ctx.mdelay = HAL_Delay;

  lsm6dso.IO.BusType = LSM6DSO_SPI_4WIRES_BUS;

  uint8_t id = 0, rst = 0;

  // Reset the IMU
  lsm6dso_reset_set(&lsm6dso.Ctx, PROPERTY_ENABLE);
  do
  {
    lsm6dso_reset_get(&lsm6dso.Ctx, &rst);
  } while (rst);

  // Read the IMU ID
  do
  {
    LSM6DSO_ReadID(&lsm6dso, &id);
    osDelay(100);
  } while (id != LSM6DSO_ID);

  // Initialize the IMU
  LSM6DSO_Init(&lsm6dso);

  // Accelerometer configuration
  LSM6DSO_ACC_SetOutputDataRate_With_Mode(&lsm6dso, 6667.0f, LSM6DSO_ACC_HIGH_PERFORMANCE_MODE);
  LSM6DSO_ACC_SetFullScale(&lsm6dso, 4);
  LSM6DSO_ACC_Set_Filter_Mode(&lsm6dso, 0, LSM6DSO_LP_ODR_DIV_20);
  LSM6DSO_ACC_Enable(&lsm6dso);

  // Gyroscope configuration
  LSM6DSO_GYRO_SetOutputDataRate_With_Mode(&lsm6dso, 6667.0f, LSM6DSO_GYRO_HIGH_PERFORMANCE_MODE);
  LSM6DSO_GYRO_SetFullScale(&lsm6dso, 500);
  LSM6DSO_GYRO_Set_Filter_Mode(&lsm6dso, 0, LSM6DSO_LP_ODR_DIV_10);
  LSM6DSO_GYRO_Enable(&lsm6dso);

  osDelay(10);

  // Accelerometer and gyroscope scale factors
  float acc_scale = 9.81 / 1000.0f;
  float gyro_scale = (3.14159265 / 180.0f) / 1000.0f;

  // LSM6DSO_Axes_t acc, gyro;
  // bool status = false;

  // // Calibrate the IMU
  // uint16_t samples = 1000;
  // Vector acc_bias(3), gyro_bias(3);

  // for (uint16_t i = 0; i < samples; i++)
  // {
  // 	LSM6DSO_ACC_GetAxes(&lsm6dso, &acc);
  // 	LSM6DSO_GYRO_GetAxes(&lsm6dso, &gyro);

  // 	acc_bias += -Vector{(float)acc.x, (float)acc.y, (float)acc.z};
  // 	gyro_bias += Vector{(float)gyro.x, (float)gyro.y, (float)gyro.z};

  // 	osDelay(2);
  // }

  // acc_bias *= (acc_scale / (float)samples);
  // gyro_bias *= (gyro_scale / (float)samples);

  // *acc_bias.z += GRAVITY; // Subtract gravity from the z-axis

  // statistics_t stats;

  LSM6DSO_Axes_t acc, gyro;

  while (1)
  {
    // printf("LSM6DSO ID: 0x%02X\n", id);

    // LSM6DSO_ACC_GetAxes(&lsm6dso, &acc);
    // LSM6DSO_GYRO_GetAxes(&lsm6dso, &gyro);

    // printf("Acceleration: %.2f %.2f %.2f Gyroscope: %.4f %.4f %.4f\n",
    //        (float)(acc.x * acc_scale),
    //        (float)(acc.y * acc_scale),
    //        (float)(acc.z * acc_scale),
    //        (float)(gyro.x * gyro_scale),
    //        (float)(gyro.y * gyro_scale),
    //        (float)(gyro.z * gyro_scale));

    // status = (LSM6DSO_ACC_GetAxes(&lsm6dso, &acc) == LSM6DSO_OK) && (LSM6DSO_GYRO_GetAxes(&lsm6dso, &gyro) == LSM6DSO_OK);

    // // Check if the IMU is active
    // if (!status || id != LSM6DSO_ID)
    // {
    // 	imu_data.active = false;

    // 	osDelay(100);
    // 	continue;
    // }

    // // Map the IMU data to the IMU data structure
    // imu_data.acceleration = (-Vector{(float)acc.x, (float)acc.y, (float)acc.z} * acc_scale - acc_bias);
    // imu_data.angular_velocity = (Vector{(float)gyro.x, (float)gyro.y, (float)gyro.z} * gyro_scale - gyro_bias);

    // imu_data.active = true;

    // ComputeStatisticsRecursive(&stats, 1000, *imu_data.angular_velocity.z);

    // Print biases
    // printf("ID: 0x%02X Acceleration: %.4f %.4f %.4f Gyroscope: %.4f %.4f %.4f\n", id, *acc_bias.x, *acc_bias.y, *acc_bias.z, *gyro_bias.x, *gyro_bias.y, *gyro_bias.z);

    // printf("ID: 0x%02X Acceleration: %.2f %.2f %.2f Gyroscope: %.4f %.4f %.4f\n", id, *imu_data.acceleration.x, *imu_data.acceleration.y, *imu_data.acceleration.z, *imu_data.angular_velocity.x, *imu_data.angular_velocity.y, *imu_data.angular_velocity.z);

    osDelay(100);
  }
}

// LIS2MDL

LIS2MDL_Object_t lis2mdl;

int32_t Write_LIS2MDL(void *handle, uint8_t reg, uint8_t *data, uint16_t len)
{
  return SPI_Write_Register(&hspi1, &spi1MutexHandle, MAG_CS_GPIO_Port, MAG_CS_Pin, reg, data, len);
}

int32_t Read_LIS2MDL(void *handle, uint8_t reg, uint8_t *data, uint16_t len)
{
  return SPI_Read_Register(&hspi1, &spi1MutexHandle, MAG_CS_GPIO_Port, MAG_CS_Pin, reg, data, len);
}

void StartMagTask(void *argument)
{
  lis2mdl.Ctx.handle = &hspi1;
  lis2mdl.Ctx.write_reg = Write_LIS2MDL;
  lis2mdl.Ctx.read_reg = Read_LIS2MDL;
  lis2mdl.Ctx.mdelay = HAL_Delay;

  lis2mdl.IO.BusType = LIS2MDL_SPI_4WIRES_BUS;

  uint8_t id = 0, rst = 0;

  // Reset the magnetometer
  lis2mdl_reset_set(&lis2mdl.Ctx, PROPERTY_ENABLE);
  do
  {
    lis2mdl_reset_get(&lis2mdl.Ctx, &rst);
  } while (rst);

  // Set the SPI mode to 4-wire
  lis2mdl_spi_mode_set(&lis2mdl.Ctx, LIS2MDL_SPI_4_WIRE);

  // Read the magnetometer ID
  do
  {
    LIS2MDL_ReadID(&lis2mdl, &id);
    osDelay(100);
  } while (id != LIS2MDL_ID);

  // Initialize the magnetometer
  LIS2MDL_Init(&lis2mdl);

  // Magnetometer configuration
  LIS2MDL_MAG_SetOutputDataRate(&lis2mdl, 100.0f);
  LIS2MDL_MAG_SetFullScale(&lis2mdl, 50);
  LIS2MDL_MAG_Set_Power_Mode(&lis2mdl, LIS2MDL_HIGH_RESOLUTION);
  LIS2MDL_MAG_Enable(&lis2mdl);

  osDelay(10);

  // Magnetometer scale factor
  float mag_scale = 1.5f / 1000.0f;
  // float RAD_TO_DEG = 180.0f / 3.14159265f;

  LIS2MDL_Axes_t mag;

  while (1)
  {
    // printf("LIS2MDL ID: 0x%02X\n", id);

    LIS2MDL_MAG_GetAxes(&lis2mdl, &mag);

    // printf("Magnetometer: %.2f %.2f %.2f\n",
    //        (float)(mag.x * mag_scale),
    //        (float)(mag.y * mag_scale),
    //        (float)(mag.z * mag_scale));

    // float roll, pitch, yaw;

    // roll = atan2(mag.y, mag.z);
    // pitch = atan2(-mag.x, sqrt(mag.y * mag.y + mag.z * mag.z));
    // yaw = atan2(mag.z, mag.x);

    // printf("Roll: %.1f Pitch: %.1f Yaw: %.1f\n", roll * RAD_TO_DEG, pitch * RAD_TO_DEG, yaw * RAD_TO_DEG);

    osDelay(100);
  }
}

// Encoders

#define AS5600_ADDR 0x36

void StartEncodersTask(void *argument)
{
  uint8_t data[2] = {0};

  while (1)
  {
    HAL_StatusTypeDef status = I2C_Read_Register(&hi2c1, &i2c1MutexHandle, 0x77, 0x0C, data, 2);

    if (status != HAL_OK)
    {
      printf("AS5600: Error\n");

      osDelay(50);
      continue;
    }

    printf("AS5600: %d\n", (data[0] << 8) | data[1]);

    osDelay(50);
  }
}

/* USER CODE END Application */
